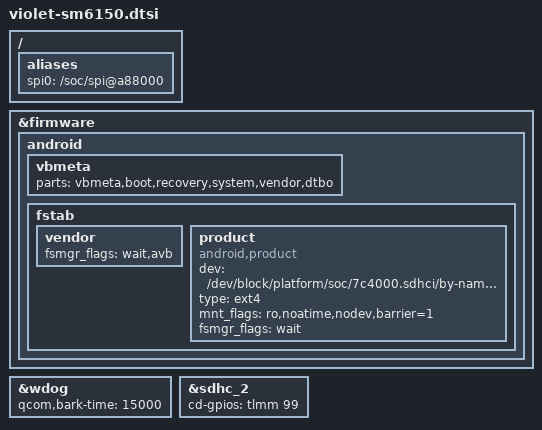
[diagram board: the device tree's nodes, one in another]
#include "../qcom-base/sm6150-idp.dtsi"
#include "violet-sm6150-audio.dtsi"
#include "violet-sm6150-battery.dtsi"
#include "violet-sm6150-camera.dtsi"
#include "violet-sm6150-display.dtsi"
#include "violet-sm6150-fingerprint.dtsi"
#include "violet-sm6150-ir.dtsi"
#include "violet-sm6150-memory.dtsi"
#include "violet-sm6150-pinctrl.dtsi"
#include "violet-sm6150-pm6150.dtsi"
#include "violet-sm6150-pm6150l.dtsi"
#include "violet-sm6150-regulator.dtsi"
#include "violet-sm6150-thermal.dtsi"
#include "violet-sm6150-touchscreen.dtsi"
#include "violet-sm6150-usb.dtsi"

/ {
	aliases {
		spi0 = "/soc/spi@a88000";
	};
};

&firmware {
	android {
		vbmeta {
			parts = "vbmeta,boot,recovery,system,vendor,dtbo";
		};

		fstab {
			vendor {
				fsmgr_flags = "wait,avb";
			};
			product {
				compatible = "android,product";
				dev = "/dev/block/platform/soc/7c4000.sdhci/by-name/cust";
				type = "ext4";
				mnt_flags = "ro,noatime,nodev,barrier=1";
				fsmgr_flags = "wait";
			};
		};
	};
};

&wdog {
	qcom,bark-time = <15000>;
};

&sdhc_2 {
	cd-gpios = <&tlmm 99 0>;
};
